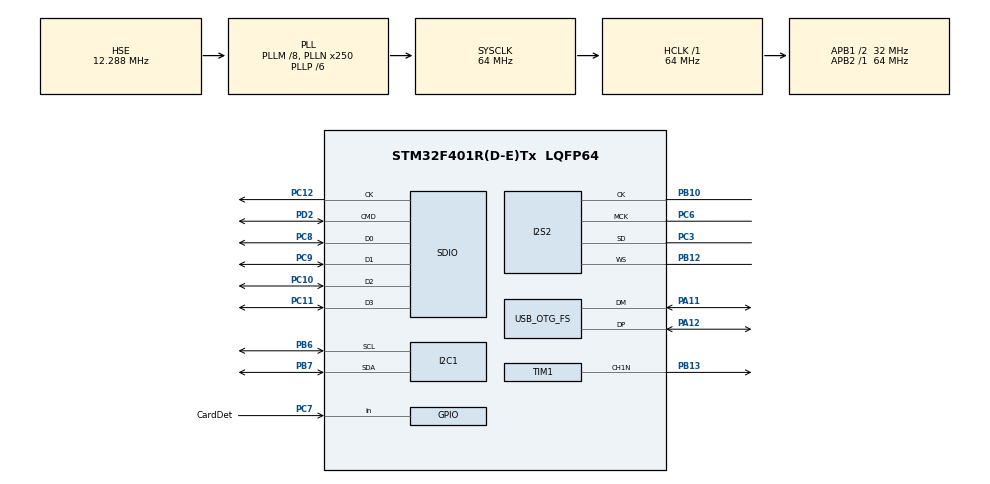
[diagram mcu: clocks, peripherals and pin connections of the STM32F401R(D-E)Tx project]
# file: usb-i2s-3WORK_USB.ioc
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Dma.Request0=SPI2_TX
Dma.SPI2_TX.0.Direction=DMA_MEMORY_TO_PERIPH
Dma.SPI2_TX.0.FIFOMode=DMA_FIFOMODE_ENABLE
Dma.SPI2_TX.0.FIFOThreshold=DMA_FIFO_THRESHOLD_FULL
Dma.SPI2_TX.0.Instance=DMA1_Stream4
Dma.SPI2_TX.0.MemBurst=DMA_MBURST_INC8
Dma.SPI2_TX.0.MemDataAlignment=DMA_MDATAALIGN_HALFWORD
Dma.SPI2_TX.0.MemInc=DMA_MINC_ENABLE
Dma.SPI2_TX.0.Mode=DMA_NORMAL
Dma.SPI2_TX.0.PeriphBurst=DMA_PBURST_SINGLE
Dma.SPI2_TX.0.PeriphDataAlignment=DMA_PDATAALIGN_HALFWORD
Dma.SPI2_TX.0.PeriphInc=DMA_PINC_DISABLE
Dma.SPI2_TX.0.Priority=DMA_PRIORITY_MEDIUM
FATFS.BSP.number=1
FATFS._CODE_PAGE=855
FATFS._USE_FIND=1
FATFS._USE_LFN=1
FATFS0.BSP.STBoard=false
FATFS0.BSP.api=Unknown
FATFS0.BSP.i2caddr=0
FATFS0.BSP.instance=PC7
FATFS0.BSP.ip=GPIO
FATFS0.BSP.mode=Input
FATFS0.BSP.name=Detect_SDIO
FATFS0.BSP.solution=PC7
I2S2.AudioFreq=I2S_AUDIOFREQ_48K
I2S2.ErrorAudioFreq=0.0 %
I2S2.FullDuplexMode=I2S_FULLDUPLEXMODE_DISABLE
I2S2.Instance=SPI$Index
I2S2.RealAudioFreq=48.0 KHz
I2S2.VirtualMode=I2S_MODE_MASTER
Mcu.Family=STM32F4
Mcu.Name=STM32F401R(D-E)Tx
Mcu.Package=LQFP64
NVIC.DMA1_Stream4_IRQn=true\:0\:0\:false\:false\:true\:false\:true
NVIC.I2C1_EV_IRQn=true\:0\:0\:false\:false\:true\:true\:true
NVIC.OTG_FS_IRQn=true\:0\:0\:false\:false\:true\:false\:true
NVIC.PriorityGroup=NVIC_PRIORITYGROUP_4
NVIC.SPI2_IRQn=true\:0\:0\:false\:false\:true\:true\:true
NVIC.TIM1_CC_IRQn=true\:0\:0\:false\:false\:true\:true\:true
PA11.Mode=Device_Only
PA11.Signal=USB_OTG_FS_DM
PA12.Mode=Device_Only
PA12.Signal=USB_OTG_FS_DP
PB10.Mode=Half_Duplex_Master
PB10.Signal=I2S2_CK
PB12.Mode=Half_Duplex_Master
PB12.Signal=I2S2_WS
PB13.Mode=PWM Generation1 CH1N
PB13.Signal=TIM1_CH1N
PB6.GPIO_Speed=GPIO_SPEED_FREQ_LOW
PB6.Mode=I2C
PB6.Signal=I2C1_SCL
PB7.GPIO_Speed=GPIO_SPEED_FREQ_LOW
PB7.Mode=I2C
PB7.Signal=I2C1_SDA
PC10.Mode=SD_4_bits_Wide_bus
PC10.Signal=SDIO_D2
PC11.Mode=SD_4_bits_Wide_bus
PC11.Signal=SDIO_D3
PC12.Mode=SD_4_bits_Wide_bus
PC12.Signal=SDIO_CK
PC3.Mode=Half_Duplex_Master
PC3.Signal=I2S2_SD
PC6.GPIO_Speed=GPIO_SPEED_FREQ_MEDIUM
PC6.Mode=Master_Clock_Activated
PC6.Signal=I2S2_MCK
PC7.GPIO_Label=CardDet
PC7.GPIO_PuPd=GPIO_PULLUP
PC7.Signal=GPIO_Input
PC8.Mode=SD_4_bits_Wide_bus
PC8.Signal=SDIO_D0
PC9.Mode=SD_4_bits_Wide_bus
PC9.Signal=SDIO_D1
PD2.Mode=SD_4_bits_Wide_bus
PD2.Signal=SDIO_CMD
PH0\ -\ OSC_IN.Mode=HSE-External-Oscillator
PH0\ -\ OSC_IN.Signal=RCC_OSC_IN
PH1\ -\ OSC_OUT.Mode=HSE-External-Oscillator
PH1\ -\ OSC_OUT.Signal=RCC_OSC_OUT
ProjectManager.HeapSize=0x4000
ProjectManager.StackSize=0x5000
ProjectManager.TargetToolchain=STM32CubeIDE
RCC.48MHZClocksFreq_Value=48000000
RCC.AHBFreq_Value=64000000
RCC.APB1CLKDivider=RCC_HCLK_DIV2
RCC.APB1Freq_Value=32000000
RCC.APB1TimFreq_Value=64000000
RCC.APB2Freq_Value=64000000
RCC.APB2TimFreq_Value=64000000
RCC.CortexFreq_Value=64000000
RCC.HCLKFreq_Value=64000000
RCC.HSE_VALUE=12288000
RCC.HSI_VALUE=16000000
RCC.LSE_VALUE=32768
RCC.PLLM=8
RCC.PLLN=250
RCC.PLLP=RCC_PLLP_DIV6
RCC.PLLQ=8
RCC.SYSCLKFreq_VALUE=64000000
RCC.SYSCLKSource=RCC_SYSCLKSOURCE_PLLCLK
RCC.VCOOutputFreq_Value=384000000
TIM1.Channel-PWM\ Generation1\ CH1N=TIM_CHANNEL_1
USB_DEVICE.CLASS_NAME_FS=AUDIO
USB_DEVICE.USBD_AUDIO_FREQ-AUDIO_FS=48000
USB_DEVICE.VirtualMode-AUDIO_FS=Audio
USB_DEVICE.VirtualModeFS=Audio_FS
USB_OTG_FS.Sof_enable=ENABLE
USB_OTG_FS.VirtualMode=Device_Only
VP_FATFS_VS_SDIO.Mode=SDIO
VP_USB_DEVICE_VS_USB_DEVICE_AUDIO_FS.Mode=AUDIO_FS
board=custom

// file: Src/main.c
/* USER CODE BEGIN Header */
/**
  ******************************************************************************
  * @file           : main.c
  * @brief          : Main program body
  ******************************************************************************
  * @attention
  *
  * <h2><center>&copy; Copyright (c) 2020 STMicroelectronics.
  * All rights reserved.</center></h2>
  *
  * This software component is licensed by ST under Ultimate Liberty license
  * SLA0044, the "License"; You may not use this file except in compliance with
  * the License. You may obtain a copy of the License at:
  *                             www.st.com/SLA0044
  *
  ******************************************************************************
  */
/* USER CODE END Header */

#include "main.h"
#include "stdio.h"
#include "fatfs.h"
#include "usb_device.h"

/* USER CODE BEGIN Includes */
#include "audioplay.h"
#include "usbd_hid.h"
#include "tlv493.h"
uint8_t  sine_wave[256] = {
  0x80, 0x83, 0x86, 0x89, 0x8C, 0x90, 0x93, 0x96,
  0x99, 0x9C, 0x9F, 0xA2, 0xA5, 0xA8, 0xAB, 0xAE,
  0xB1, 0xB3, 0xB6, 0xB9, 0xBC, 0xBF, 0xC1, 0xC4,
  0xC7, 0xC9, 0xCC, 0xCE, 0xD1, 0xD3, 0xD5, 0xD8,
  0xDA, 0xDC, 0xDE, 0xE0, 0xE2, 0xE4, 0xE6, 0xE8,
  0xEA, 0xEB, 0xED, 0xEF, 0xF0, 0xF1, 0xF3, 0xF4,
  0xF5, 0xF6, 0xF8, 0xF9, 0xFA, 0xFA, 0xFB, 0xFC,
  0xFD, 0xFD, 0xFE, 0xFE, 0xFE, 0xFF, 0xFF, 0xFF,
  0xFF, 0xFF, 0xFF, 0xFF, 0xFE, 0xFE, 0xFE, 0xFD,
  0xFD, 0xFC, 0xFB, 0xFA, 0xFA, 0xF9, 0xF8, 0xF6,
  0xF5, 0xF4, 0xF3, 0xF1, 0xF0, 0xEF, 0xED, 0xEB,
  0xEA, 0xE8, 0xE6, 0xE4, 0xE2, 0xE0, 0xDE, 0xDC,
  0xDA, 0xD8, 0xD5, 0xD3, 0xD1, 0xCE, 0xCC, 0xC9,
  0xC7, 0xC4, 0xC1, 0xBF, 0xBC, 0xB9, 0xB6, 0xB3,
  0xB1, 0xAE, 0xAB, 0xA8, 0xA5, 0xA2, 0x9F, 0x9C,
  0x99, 0x96, 0x93, 0x90, 0x8C, 0x89, 0x86, 0x83,
  0x80, 0x7D, 0x7A, 0x77, 0x74, 0x70, 0x6D, 0x6A,
  0x67, 0x64, 0x61, 0x5E, 0x5B, 0x58, 0x55, 0x52,
  0x4F, 0x4D, 0x4A, 0x47, 0x44, 0x41, 0x3F, 0x3C,
  0x39, 0x37, 0x34, 0x32, 0x2F, 0x2D, 0x2B, 0x28,
  0x26, 0x24, 0x22, 0x20, 0x1E, 0x1C, 0x1A, 0x18,
  0x16, 0x15, 0x13, 0x11, 0x10, 0x0F, 0x0D, 0x0C,
  0x0B, 0x0A, 0x08, 0x07, 0x06, 0x06, 0x05, 0x04,
  0x03, 0x03, 0x02, 0x02, 0x02, 0x01, 0x01, 0x01,
  0x01, 0x01, 0x01, 0x01, 0x02, 0x02, 0x02, 0x03,
  0x03, 0x04, 0x05, 0x06, 0x06, 0x07, 0x08, 0x0A,
  0x0B, 0x0C, 0x0D, 0x0F, 0x10, 0x11, 0x13, 0x15,
  0x16, 0x18, 0x1A, 0x1C, 0x1E, 0x20, 0x22, 0x24,
  0x26, 0x28, 0x2B, 0x2D, 0x2F, 0x32, 0x34, 0x37,
  0x39, 0x3C, 0x3F, 0x41, 0x44, 0x47, 0x4A, 0x4D,
  0x4F, 0x52, 0x55, 0x58, 0x5B, 0x5E, 0x61, 0x64,
  0x67, 0x6A, 0x6D, 0x70, 0x74, 0x77, 0x7A, 0x7D
};
/* USER CODE END Includes */

I2C_HandleTypeDef hi2c1;

I2S_HandleTypeDef hi2s2;
DMA_HandleTypeDef hdma_spi2_tx;

SD_HandleTypeDef hsd;

TIM_HandleTypeDef htim1;

void SystemClock_Config(void);
static void MX_GPIO_Init(void);
static void MX_DMA_Init(void);
static void MX_I2C1_Init(void);
static void MX_I2S2_Init(void);
static void MX_SDIO_SD_Init(void);
static void MX_TIM1_Init(void);
/* USER CODE BEGIN PFP */
#define MAG_VAL 4
extern USBD_HandleTypeDef hUsbDeviceFS;
uint8_t HID_Buffer[8];
int ledBright=0;

int phoneUp=0;
int phoneUp_=2;

float a=0;
float b=0;
float d=0;

int increment=400;
int targetBright;
/* USER CODE END PFP */

/* USER CODE BEGIN 0 */
/*
 * 	    0x09, 0xb5,                    //   USAGE (Scan Next Track)
	    0x09, 0xb6,                    //   USAGE (Scan Previous Track)
	    0x09, 0xb7,                    //   USAGE (Stop)
	    0x09, 0xb0,                    //   USAGE (Play)
	    0x09, 0xe2,                    //   USAGE (Mute)
	    0x09, 0xe9,                    //   USAGE (Volume Up)
	    0x09, 0xea,                    //   USAGE (Volume Down)
 */
static void hid_send_stop()
{
	HID_Buffer[0]=0;
	HID_Buffer[1]=0;
	HID_Buffer[2]=22;
	//HID_Buffer[1]=0x00;
	//HID_Buffer[2]=0;
	USBD_HID_SendReport(&hUsbDeviceFS,HID_Buffer,8);
	HAL_Delay(20);

	HID_Buffer[0]=0;
	HID_Buffer[1]=0;
	HID_Buffer[2]=0;
	//HID_Buffer[2]=0;
	USBD_HID_SendReport(&hUsbDeviceFS,HID_Buffer,8);
}
static void hid_send_start()
{
	HID_Buffer[0]=0;
	HID_Buffer[1]=0;
	HID_Buffer[2]=19;
	USBD_HID_SendReport(&hUsbDeviceFS,HID_Buffer,8);
	HAL_Delay(20);

	HID_Buffer[0]=0;
	HID_Buffer[1]=0;
	HID_Buffer[2]=0;
	USBD_HID_SendReport(&hUsbDeviceFS,HID_Buffer,8);
}

void setLed(int targetBright){
	targetBright=targetBright-targetBright%increment;

	if(ledBright!=targetBright){
		if(targetBright>ledBright){ ledBright+=increment;}
		else { ledBright-=increment;}
		TIM1->CCR1=ledBright;
		HAL_Delay(1);
	}
}

/* USER CODE END 0 */

int main(void)
{

  /* MCU Configuration--------------------------------------------------------*/

  /* Reset of all peripherals, Initializes the Flash interface and the Systick. */
  HAL_Init();

  /* Configure the system clock */
  SystemClock_Config();

  /* Initialize all configured peripherals */
  MX_GPIO_Init();
  MX_DMA_Init();
  MX_USB_DEVICE_Init();
  MX_I2C1_Init();
  MX_I2S2_Init();
  MX_SDIO_SD_Init();
  MX_FATFS_Init();
  MX_TIM1_Init();

  HAL_TIMEx_PWMN_Start(&htim1, TIM_CHANNEL_1);

  /* Infinite loop */
  /* USER CODE BEGIN WHILE */
  //setLed(65535);
  //HAL_Delay(1000);
  //setLed(0);
  //HAL_Delay(100);

  for( int u = 0; u<100; u++){
	    a=0.995*a+0.005*getMagVal();
	    b=0.7*b+0.3*getMagVal();
  }

  if(a<13){phoneUp=1;}

  printf("dsfsda: \n");
  while (1)
  {

	  //a=getMagVal();
    a=0.992*a+0.008*getMagVal();
    b=0.95*b+0.05*getMagVal();
    d = a-b;
    if (d>MAG_VAL){
	  	  phoneUp=1;
  	} else if (d<-MAG_VAL) {
  		  phoneUp=0;
  	}

	if (phoneUp!=phoneUp_){
		if (phoneUp){
			hid_send_start();
			//setLed(500);
			targetBright = 500;
			targetBright=targetBright-targetBright%increment;
		}else{
			hid_send_stop();
			//setLed(65533);
			targetBright = 65533;
			targetBright=targetBright-targetBright%increment;
		}
	 }
	  phoneUp_=phoneUp;

		if(ledBright!=targetBright){
			if(targetBright>ledBright){ ledBright+=increment;}
			else { ledBright-=increment;}
			TIM1->CCR1=ledBright;
			//HAL_Delay(1);
		}
	  //printf("d: %d \n",(int)(d*1000));
	  HAL_Delay(1 );
  }

  /* USER CODE END 3 */
}

void SystemClock_Config(void)
{
  RCC_OscInitTypeDef RCC_OscInitStruct = {0};
  RCC_ClkInitTypeDef RCC_ClkInitStruct = {0};
  RCC_PeriphCLKInitTypeDef PeriphClkInitStruct = {0};

  /** Configure the main internal regulator output voltage
  */
  __HAL_RCC_PWR_CLK_ENABLE();
  __HAL_PWR_VOLTAGESCALING_CONFIG(PWR_REGULATOR_VOLTAGE_SCALE2);
  /** Initializes the CPU, AHB and APB busses clocks
  */
  RCC_OscInitStruct.OscillatorType = RCC_OSCILLATORTYPE_HSE;
  RCC_OscInitStruct.HSEState = RCC_HSE_ON;
  RCC_OscInitStruct.PLL.PLLState = RCC_PLL_ON;
  RCC_OscInitStruct.PLL.PLLSource = RCC_PLLSOURCE_HSE;
  RCC_OscInitStruct.PLL.PLLM = 8;
  RCC_OscInitStruct.PLL.PLLN = 250;
  RCC_OscInitStruct.PLL.PLLP = RCC_PLLP_DIV6;
  RCC_OscInitStruct.PLL.PLLQ = 8;
  if (HAL_RCC_OscConfig(&RCC_OscInitStruct) != HAL_OK)
  {
    Error_Handler();
  }
  /** Initializes the CPU, AHB and APB busses clocks
  */
  RCC_ClkInitStruct.ClockType = RCC_CLOCKTYPE_HCLK|RCC_CLOCKTYPE_SYSCLK
                              |RCC_CLOCKTYPE_PCLK1|RCC_CLOCKTYPE_PCLK2;
  RCC_ClkInitStruct.SYSCLKSource = RCC_SYSCLKSOURCE_PLLCLK;
  RCC_ClkInitStruct.AHBCLKDivider = RCC_SYSCLK_DIV1;
  RCC_ClkInitStruct.APB1CLKDivider = RCC_HCLK_DIV2;
  RCC_ClkInitStruct.APB2CLKDivider = RCC_HCLK_DIV1;

  if (HAL_RCC_ClockConfig(&RCC_ClkInitStruct, FLASH_LATENCY_2) != HAL_OK)
  {
    Error_Handler();
  }
  PeriphClkInitStruct.PeriphClockSelection = RCC_PERIPHCLK_I2S;
  PeriphClkInitStruct.PLLI2S.PLLI2SN = 192;
  PeriphClkInitStruct.PLLI2S.PLLI2SR = 2;
  if (HAL_RCCEx_PeriphCLKConfig(&PeriphClkInitStruct) != HAL_OK)
  {
    Error_Handler();
  }
}

static void MX_I2C1_Init(void)
{

  hi2c1.Instance = I2C1;
  hi2c1.Init.ClockSpeed = 100000;
  hi2c1.Init.DutyCycle = I2C_DUTYCYCLE_2;
  hi2c1.Init.OwnAddress1 = 0;
  hi2c1.Init.AddressingMode = I2C_ADDRESSINGMODE_7BIT;
  hi2c1.Init.DualAddressMode = I2C_DUALADDRESS_DISABLE;
  hi2c1.Init.OwnAddress2 = 0;
  hi2c1.Init.GeneralCallMode = I2C_GENERALCALL_DISABLE;
  hi2c1.Init.NoStretchMode = I2C_NOSTRETCH_DISABLE;
  if (HAL_I2C_Init(&hi2c1) != HAL_OK)
  {
    Error_Handler();
  }

}

static void MX_I2S2_Init(void)
{

  hi2s2.Instance = SPI2;
  hi2s2.Init.Mode = I2S_MODE_MASTER_TX;
  hi2s2.Init.Standard = I2S_STANDARD_PHILIPS;
  hi2s2.Init.DataFormat = I2S_DATAFORMAT_16B;
  hi2s2.Init.MCLKOutput = I2S_MCLKOUTPUT_ENABLE;
  hi2s2.Init.AudioFreq = I2S_AUDIOFREQ_48K;
  hi2s2.Init.CPOL = I2S_CPOL_LOW;
  hi2s2.Init.ClockSource = I2S_CLOCK_PLL;
  hi2s2.Init.FullDuplexMode = I2S_FULLDUPLEXMODE_DISABLE;
  if (HAL_I2S_Init(&hi2s2) != HAL_OK)
  {
    Error_Handler();
  }

}

static void MX_SDIO_SD_Init(void)
{

  hsd.Instance = SDIO;
  hsd.Init.ClockEdge = SDIO_CLOCK_EDGE_RISING;
  hsd.Init.ClockBypass = SDIO_CLOCK_BYPASS_DISABLE;
  hsd.Init.ClockPowerSave = SDIO_CLOCK_POWER_SAVE_DISABLE;
  hsd.Init.BusWide = SDIO_BUS_WIDE_1B;
  hsd.Init.HardwareFlowControl = SDIO_HARDWARE_FLOW_CONTROL_DISABLE;
  hsd.Init.ClockDiv = 0;

}

static void MX_TIM1_Init(void)
{

  TIM_MasterConfigTypeDef sMasterConfig = {0};
  TIM_OC_InitTypeDef sConfigOC = {0};
  TIM_BreakDeadTimeConfigTypeDef sBreakDeadTimeConfig = {0};

  htim1.Instance = TIM1;
  htim1.Init.Prescaler = 0;
  htim1.Init.CounterMode = TIM_COUNTERMODE_UP;
  htim1.Init.Period = 65534;
  htim1.Init.ClockDivision = TIM_CLOCKDIVISION_DIV1;
  htim1.Init.RepetitionCounter = 0;
  htim1.Init.AutoReloadPreload = TIM_AUTORELOAD_PRELOAD_DISABLE;
  if (HAL_TIM_PWM_Init(&htim1) != HAL_OK)
  {
    Error_Handler();
  }
  sMasterConfig.MasterOutputTrigger = TIM_TRGO_RESET;
  sMasterConfig.MasterSlaveMode = TIM_MASTERSLAVEMODE_DISABLE;
  if (HAL_TIMEx_MasterConfigSynchronization(&htim1, &sMasterConfig) != HAL_OK)
  {
    Error_Handler();
  }
  sConfigOC.OCMode = TIM_OCMODE_PWM1;
  sConfigOC.Pulse = 0;
  sConfigOC.OCPolarity = TIM_OCPOLARITY_HIGH;
  sConfigOC.OCNPolarity = TIM_OCNPOLARITY_HIGH;
  sConfigOC.OCFastMode = TIM_OCFAST_DISABLE;
  sConfigOC.OCIdleState = TIM_OCIDLESTATE_RESET;
  sConfigOC.OCNIdleState = TIM_OCNIDLESTATE_RESET;
  if (HAL_TIM_PWM_ConfigChannel(&htim1, &sConfigOC, TIM_CHANNEL_1) != HAL_OK)
  {
    Error_Handler();
  }
  sBreakDeadTimeConfig.OffStateRunMode = TIM_OSSR_DISABLE;
  sBreakDeadTimeConfig.OffStateIDLEMode = TIM_OSSI_DISABLE;
  sBreakDeadTimeConfig.LockLevel = TIM_LOCKLEVEL_OFF;
  sBreakDeadTimeConfig.DeadTime = 0;
  sBreakDeadTimeConfig.BreakState = TIM_BREAK_DISABLE;
  sBreakDeadTimeConfig.BreakPolarity = TIM_BREAKPOLARITY_HIGH;
  sBreakDeadTimeConfig.AutomaticOutput = TIM_AUTOMATICOUTPUT_DISABLE;
  if (HAL_TIMEx_ConfigBreakDeadTime(&htim1, &sBreakDeadTimeConfig) != HAL_OK)
  {
    Error_Handler();
  }
  HAL_TIM_MspPostInit(&htim1);

}

static void MX_DMA_Init(void)
{

  /* DMA controller clock enable */
  __HAL_RCC_DMA1_CLK_ENABLE();

  /* DMA interrupt init */
  /* DMA1_Stream4_IRQn interrupt configuration */
  HAL_NVIC_SetPriority(DMA1_Stream4_IRQn, 0, 0);
  HAL_NVIC_EnableIRQ(DMA1_Stream4_IRQn);

}

static void MX_GPIO_Init(void)
{
  GPIO_InitTypeDef GPIO_InitStruct = {0};

  /* GPIO Ports Clock Enable */
  __HAL_RCC_GPIOH_CLK_ENABLE();
  __HAL_RCC_GPIOC_CLK_ENABLE();
  __HAL_RCC_GPIOB_CLK_ENABLE();
  __HAL_RCC_GPIOA_CLK_ENABLE();
  __HAL_RCC_GPIOD_CLK_ENABLE();

  /*Configure GPIO pin : PA7 */
  GPIO_InitStruct.Pin = GPIO_PIN_7;
  GPIO_InitStruct.Mode = GPIO_MODE_OUTPUT_PP;
  GPIO_InitStruct.Pull = GPIO_PULLDOWN;
  GPIO_InitStruct.Speed = GPIO_SPEED_FREQ_LOW;
  HAL_GPIO_Init(GPIOA, &GPIO_InitStruct);

  /*Configure GPIO pin : CardDet_Pin */
  GPIO_InitStruct.Pin = CardDet_Pin;
  GPIO_InitStruct.Mode = GPIO_MODE_INPUT;
  GPIO_InitStruct.Pull = GPIO_PULLUP;
  HAL_GPIO_Init(CardDet_GPIO_Port, &GPIO_InitStruct);

}

/* USER CODE BEGIN 4 */
void HAL_I2S_TxCpltCallback(I2S_HandleTypeDef *hi2s2)
{
	if(hi2s2->Instance==I2S2)
	{
		AudioPlay_TransferComplete_CallBack();
	}
}
//---------------------------------------------------------
void HAL_I2S_TxHalfCpltCallback(I2S_HandleTypeDef *hi2s2)
{
	if(hi2s2->Instance==I2S2)
	{
		AudioPlay_HalfTransfer_CallBack();
	}
}
/* USER CODE END 4 */

void Error_Handler(void)
{
}

/************************ (C) COPYRIGHT STMicroelectronics *****END OF FILE****/
